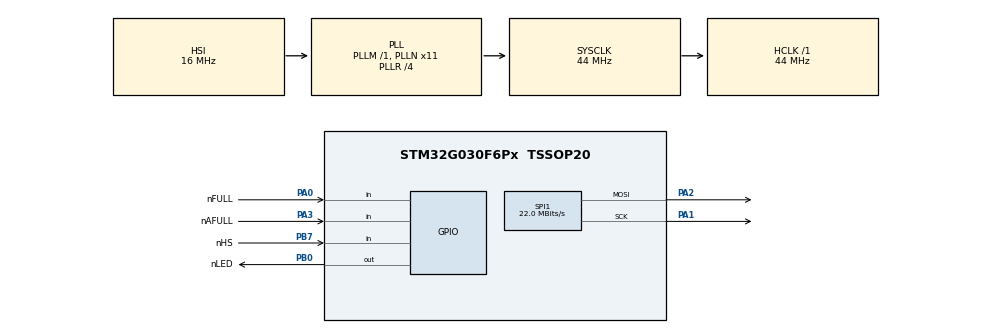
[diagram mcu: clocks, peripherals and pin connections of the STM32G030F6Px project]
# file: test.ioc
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Dma.Request0=SPI1_TX
Dma.SPI1_TX.0.Direction=DMA_MEMORY_TO_PERIPH
Dma.SPI1_TX.0.EventEnable=DISABLE
Dma.SPI1_TX.0.Instance=DMA1_Channel1
Dma.SPI1_TX.0.MemDataAlignment=DMA_MDATAALIGN_HALFWORD
Dma.SPI1_TX.0.MemInc=DMA_MINC_ENABLE
Dma.SPI1_TX.0.Mode=DMA_NORMAL
Dma.SPI1_TX.0.PeriphDataAlignment=DMA_PDATAALIGN_HALFWORD
Dma.SPI1_TX.0.PeriphInc=DMA_PINC_DISABLE
Dma.SPI1_TX.0.Polarity=HAL_DMAMUX_REQ_GEN_RISING
Dma.SPI1_TX.0.Priority=DMA_PRIORITY_LOW
Dma.SPI1_TX.0.RequestNumber=1
Dma.SPI1_TX.0.SignalID=NONE
Dma.SPI1_TX.0.SyncEnable=DISABLE
Dma.SPI1_TX.0.SyncPolarity=HAL_DMAMUX_SYNC_NO_EVENT
Dma.SPI1_TX.0.SyncRequestNumber=1
Dma.SPI1_TX.0.SyncSignalID=NONE
Mcu.Family=STM32G0
Mcu.Name=STM32G030F6Px
Mcu.Package=TSSOP20
NVIC.DMA1_Channel1_IRQn=true\:0\:0\:false\:false\:true\:false\:true
PA0.GPIO_Label=nFULL
PA0.GPIO_PuPd=GPIO_PULLDOWN
PA0.Signal=GPIO_Input
PA1.GPIO_Speed=GPIO_SPEED_FREQ_VERY_HIGH
PA1.Mode=TX_Only_Simplex_Unidirect_Master
PA1.Signal=SPI1_SCK
PA2.GPIO_Speed=GPIO_SPEED_FREQ_VERY_HIGH
PA2.Mode=TX_Only_Simplex_Unidirect_Master
PA2.Signal=SPI1_MOSI
PA3.GPIO_Label=nAFULL
PA3.GPIO_PuPd=GPIO_PULLDOWN
PA3.Signal=GPIO_Input
PB0.GPIO_Label=nLED
PB0.PinState=GPIO_PIN_SET
PB0.Signal=GPIO_Output
PB7.GPIO_Label=nHS
PB7.GPIO_PuPd=GPIO_PULLUP
PB7.Signal=GPIO_Input
ProjectManager.HeapSize=0x200
ProjectManager.StackSize=0x400
ProjectManager.TargetToolchain=EWARM V8.32
RCC.ADCFreq_Value=44000000
RCC.AHBFreq_Value=44000000
RCC.CortexFreq_Value=44000000
RCC.EXTERNAL_CLOCK_VALUE=12288000
RCC.HCLKFreq_Value=44000000
RCC.HSE_VALUE=8000000
RCC.HSI_VALUE=16000000
RCC.LSE_VALUE=32768
RCC.PLLN=11
RCC.PLLR=RCC_PLLR_DIV4
RCC.SYSCLKFreq_VALUE=44000000
RCC.SYSCLKSource=RCC_SYSCLKSOURCE_PLLCLK
RCC.VCOOutputFreq_Value=176000000
SPI1.BaudRatePrescaler=SPI_BAUDRATEPRESCALER_2
SPI1.CLKPhase=SPI_PHASE_2EDGE
SPI1.CLKPolarity=SPI_POLARITY_HIGH
SPI1.CalculateBaudRate=22.0 MBits/s
SPI1.DataSize=SPI_DATASIZE_16BIT
SPI1.Direction=SPI_DIRECTION_2LINES
SPI1.FirstBit=SPI_FIRSTBIT_LSB
SPI1.Mode=SPI_MODE_MASTER
SPI1.VirtualType=VM_MASTER
board=custom

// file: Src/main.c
/* USER CODE BEGIN Header */
/**
  ******************************************************************************
  * @file           : main.c
  * @brief          : Main program body
  ******************************************************************************
  * @attention
  *
  * <h2><center>&copy; Copyright (c) 2023 STMicroelectronics.
  * All rights reserved.</center></h2>
  *
  * This software component is licensed by ST under BSD 3-Clause license,
  * the "License"; You may not use this file except in compliance with the
  * License. You may obtain a copy of the License at:
  *                        opensource.org/licenses/BSD-3-Clause
  *
  ******************************************************************************
  */
/* USER CODE END Header */

#include "main.h"

/* USER CODE BEGIN Includes */
#include "test.h"
/* USER CODE END Includes */

SPI_HandleTypeDef hspi1;
DMA_HandleTypeDef hdma_spi1_tx;

void SystemClock_Config(void);
static void MX_GPIO_Init(void);
static void MX_SPI1_Init(void);
static void MX_DMA_Init(void);

int main(void)
{

  /* MCU Configuration--------------------------------------------------------*/

  /* Reset of all peripherals, Initializes the Flash interface and the Systick. */
  HAL_Init();

  /* Configure the system clock */
  SystemClock_Config();

  /* USER CODE BEGIN SysInit */
  MX_DMA_Init();
  /* USER CODE END SysInit */

  /* Initialize all configured peripherals */
  MX_GPIO_Init();
  MX_SPI1_Init();
  /* USER CODE BEGIN 2 */
  test_init();
  /* USER CODE END 2 */

  /* Infinite loop */
  while (1)
  {

    /* USER CODE BEGIN 3 */
    test_run();
    test_idle();
  }
  /* USER CODE END 3 */
}

void SystemClock_Config(void)
{
  RCC_OscInitTypeDef RCC_OscInitStruct = {0};
  RCC_ClkInitTypeDef RCC_ClkInitStruct = {0};

  /** Configure the main internal regulator output voltage
  */
  HAL_PWREx_ControlVoltageScaling(PWR_REGULATOR_VOLTAGE_SCALE1);
  /** Initializes the CPU, AHB and APB busses clocks
  */
  RCC_OscInitStruct.OscillatorType = RCC_OSCILLATORTYPE_HSI;
  RCC_OscInitStruct.HSIState = RCC_HSI_ON;
  RCC_OscInitStruct.HSIDiv = RCC_HSI_DIV1;
  RCC_OscInitStruct.HSICalibrationValue = RCC_HSICALIBRATION_DEFAULT;
  RCC_OscInitStruct.PLL.PLLState = RCC_PLL_ON;
  RCC_OscInitStruct.PLL.PLLSource = RCC_PLLSOURCE_HSI;
  RCC_OscInitStruct.PLL.PLLM = RCC_PLLM_DIV1;
  RCC_OscInitStruct.PLL.PLLN = 11;
  RCC_OscInitStruct.PLL.PLLP = RCC_PLLP_DIV2;
  RCC_OscInitStruct.PLL.PLLR = RCC_PLLR_DIV4;
  if (HAL_RCC_OscConfig(&RCC_OscInitStruct) != HAL_OK)
  {
    Error_Handler();
  }
  /** Initializes the CPU, AHB and APB busses clocks
  */
  RCC_ClkInitStruct.ClockType = RCC_CLOCKTYPE_HCLK|RCC_CLOCKTYPE_SYSCLK
                              |RCC_CLOCKTYPE_PCLK1;
  RCC_ClkInitStruct.SYSCLKSource = RCC_SYSCLKSOURCE_PLLCLK;
  RCC_ClkInitStruct.AHBCLKDivider = RCC_SYSCLK_DIV1;
  RCC_ClkInitStruct.APB1CLKDivider = RCC_HCLK_DIV1;

  if (HAL_RCC_ClockConfig(&RCC_ClkInitStruct, FLASH_LATENCY_1) != HAL_OK)
  {
    Error_Handler();
  }
}

static void MX_SPI1_Init(void)
{

  /* SPI1 parameter configuration*/
  hspi1.Instance = SPI1;
  hspi1.Init.Mode = SPI_MODE_MASTER;
  hspi1.Init.Direction = SPI_DIRECTION_2LINES;
  hspi1.Init.DataSize = SPI_DATASIZE_16BIT;
  hspi1.Init.CLKPolarity = SPI_POLARITY_HIGH;
  hspi1.Init.CLKPhase = SPI_PHASE_2EDGE;
  hspi1.Init.NSS = SPI_NSS_SOFT;
  hspi1.Init.BaudRatePrescaler = SPI_BAUDRATEPRESCALER_2;
  hspi1.Init.FirstBit = SPI_FIRSTBIT_LSB;
  hspi1.Init.TIMode = SPI_TIMODE_DISABLE;
  hspi1.Init.CRCCalculation = SPI_CRCCALCULATION_DISABLE;
  hspi1.Init.CRCPolynomial = 7;
  hspi1.Init.CRCLength = SPI_CRC_LENGTH_DATASIZE;
  hspi1.Init.NSSPMode = SPI_NSS_PULSE_DISABLE;
  if (HAL_SPI_Init(&hspi1) != HAL_OK)
  {
    Error_Handler();
  }

}

static void MX_DMA_Init(void)
{

  /* DMA controller clock enable */
  __HAL_RCC_DMA1_CLK_ENABLE();

  /* DMA interrupt init */
  /* DMA1_Channel1_IRQn interrupt configuration */
  HAL_NVIC_SetPriority(DMA1_Channel1_IRQn, 0, 0);
  HAL_NVIC_EnableIRQ(DMA1_Channel1_IRQn);

}

static void MX_GPIO_Init(void)
{
  GPIO_InitTypeDef GPIO_InitStruct = {0};

  /* GPIO Ports Clock Enable */
  __HAL_RCC_GPIOB_CLK_ENABLE();
  __HAL_RCC_GPIOA_CLK_ENABLE();

  /*Configure GPIO pin Output Level */
  HAL_GPIO_WritePin(nLED_GPIO_Port, nLED_Pin, GPIO_PIN_SET);

  /*Configure GPIO pin : nHS_Pin */
  GPIO_InitStruct.Pin = nHS_Pin;
  GPIO_InitStruct.Mode = GPIO_MODE_INPUT;
  GPIO_InitStruct.Pull = GPIO_PULLUP;
  HAL_GPIO_Init(nHS_GPIO_Port, &GPIO_InitStruct);

  /*Configure GPIO pins : nFULL_Pin nAFULL_Pin */
  GPIO_InitStruct.Pin = nFULL_Pin|nAFULL_Pin;
  GPIO_InitStruct.Mode = GPIO_MODE_INPUT;
  GPIO_InitStruct.Pull = GPIO_PULLDOWN;
  HAL_GPIO_Init(GPIOA, &GPIO_InitStruct);

  /*Configure GPIO pin : nLED_Pin */
  GPIO_InitStruct.Pin = nLED_Pin;
  GPIO_InitStruct.Mode = GPIO_MODE_OUTPUT_PP;
  GPIO_InitStruct.Pull = GPIO_NOPULL;
  GPIO_InitStruct.Speed = GPIO_SPEED_FREQ_LOW;
  HAL_GPIO_Init(nLED_GPIO_Port, &GPIO_InitStruct);

}

void Error_Handler(void)
{
}

/************************ (C) COPYRIGHT STMicroelectronics *****END OF FILE****/
